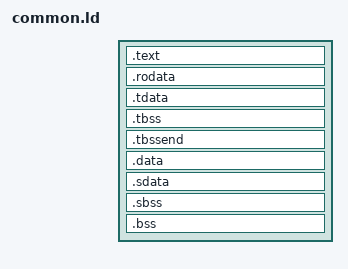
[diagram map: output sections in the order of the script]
/* Copyright 2020 ETH Zurich and University of Bologna. */
/* Solderpad Hardware License, Version 0.51, see LICENSE for details. */
/* SPDX-License-Identifier: SHL-0.51 */

OUTPUT_ARCH( "riscv" )
ENTRY(_start)

SECTIONS
{
  /* The program code and other data goes into DRAM */
  .text :
  {
    . = ALIGN(4);
    *(.text.init)
    *(.text.startup)
    *(.text)
    *(.text*)
    *(.text)
    . = ALIGN(4);
    _etext = .;
  }

  /* Constant data goes into BRAM */
  .rodata :
  {
    . = ALIGN(4);
    *(.rodata)
    *(.rodata*)
    . = ALIGN(4);
  }

  /* Thread Local Storage sections  */
  .tdata    :
  {
    __tdata_start = .;
    *(.tdata .tdata.* .gnu.linkonce.td.*)
    __tdata_end = .;
  }
  .tbss : 
  { 
    __tbss_start = .;
    *(.tbss .tbss.* .gnu.linkonce.tb.*) 
    *(.tcommon)
    __tbss_end = .;
  }
  /* add a section after .tbss to put the __tbss_end symbol into for
     the LLD linker */
  .tbssend : { __tbss_end2 = .; } 
  
  /* Initialized data sections goes into L1, load LMA copy after code */
  .data : 
  {
    __DATA_BEGIN__ = .;
    *(.data .data.* .gnu.linkonce.d.*)
    SORT(CONSTRUCTORS)
  }

  /* small data section that can be addressed through the global pointer */
  .sdata          :
  {
    __SDATA_BEGIN__ = .;
    *(.srodata.cst16) *(.srodata.cst8) *(.srodata.cst4) *(.srodata.cst2) *(.srodata .srodata.*)
    *(.sdata .sdata.* .gnu.linkonce.s.*)
  }
  _edata = .; PROVIDE (edata = .);

  /* small bss section */
  . = .;
  __bss_start = .;
  .sbss           :
  {
    *(.dynsbss)
    *(.sbss .sbss.* .gnu.linkonce.sb.*)
    *(.scommon)
  }

  /* Uninitialized data section */
  .bss            :
  {
   *(.dynbss)
   *(.bss .bss.* .gnu.linkonce.b.*)
   *(COMMON)
   /* Align here to ensure that the .bss section occupies space up to
      _end.  Align after .bss to ensure correct alignment even if the
      .bss section disappears because there are no input sections. */
   . = ALIGN(. != 0 ? 32 / 8 : 1);
  }
  . = ALIGN(32 / 8);
  . = SEGMENT_START("ldata-segment", .);
  . = ALIGN(32 / 8);
  __BSS_END__ = .;
  __global_pointer$ = MIN(__SDATA_BEGIN__ + 0x800,
              MAX(__DATA_BEGIN__ + 0x800, __BSS_END__ - 0x800));
  _end = .; PROVIDE (end = .);
}
